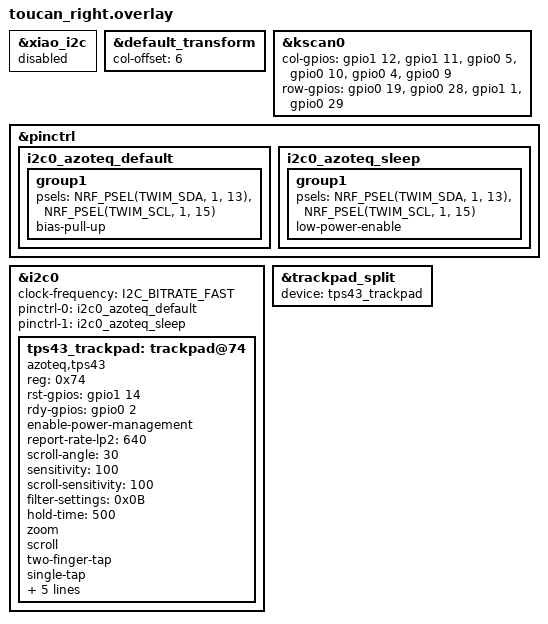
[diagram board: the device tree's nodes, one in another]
#include "toucan.dtsi"
#include <input/processors.dtsi>
#include <dt-bindings/zmk/input_transform.h>
#include <zephyr/dt-bindings/i2c/i2c.h>

&xiao_i2c {
    status = "disabled";
};

&default_transform {
    col-offset = <6>;
};

&kscan0 {
    col-gpios
    = <&gpio1 12 GPIO_ACTIVE_HIGH>
    , <&gpio1 11 GPIO_ACTIVE_HIGH>
    , <&gpio0 5 GPIO_ACTIVE_HIGH>
    , <&gpio0 10 GPIO_ACTIVE_HIGH>
    , <&gpio0 4 GPIO_ACTIVE_HIGH>
    , <&gpio0 9 GPIO_ACTIVE_HIGH>
    ;

    row-gpios
    = <&gpio0 19 (GPIO_ACTIVE_HIGH | GPIO_PULL_DOWN)>
    , <&gpio0 28 (GPIO_ACTIVE_HIGH | GPIO_PULL_DOWN)>
    , <&gpio1 1 (GPIO_ACTIVE_HIGH | GPIO_PULL_DOWN)>
    , <&gpio0 29 (GPIO_ACTIVE_HIGH | GPIO_PULL_DOWN)>
    ;
};

&pinctrl {
    i2c0_azoteq_default: i2c0_azoteq_default {
        group1 {
            psels = <NRF_PSEL(TWIM_SDA, 1, 13)>,
                    <NRF_PSEL(TWIM_SCL, 1, 15)>;
            bias-pull-up;
        };
    };

    i2c0_azoteq_sleep: i2c0_azoteq_sleep {
        group1 {
            psels = <NRF_PSEL(TWIM_SDA, 1, 13)>,
                    <NRF_PSEL(TWIM_SCL, 1, 15)>;
            low-power-enable;
        };
    };
};

&i2c0 {
    status = "okay";
    clock-frequency = <I2C_BITRATE_FAST>;
    pinctrl-0 = <&i2c0_azoteq_default>;
    pinctrl-1 = <&i2c0_azoteq_sleep>;
    pinctrl-names = "default", "sleep";

    tps43_trackpad: trackpad@74 {
        compatible = "azoteq,tps43";
        reg = <0x74>;
        status = "okay";

        rst-gpios = <&gpio1 14 GPIO_ACTIVE_HIGH>;
        rdy-gpios = <&gpio0 2 GPIO_ACTIVE_HIGH>;

        enable-power-management;
        // idle-sleep provides maximal power savings, but the pad stops responding
        // to touch until the next ZMK-active keypress while the keyboard is idle.
        // Not enabled: tps43_idle_sleeper.c already coordinates with ZMK activity state.
        report-rate-lp2 = <640>;  // 55uA in LP2 vs 174uA at the 160ms default

        // NOTE: orientation is copied from beekeeb/zmk-keyboard-toucan2 and is
        // UNVERIFIED for this retrofit — confirm on hardware and adjust
        // switch-xy / invert-x / invert-y / invert-scroll-x / invert-scroll-y.
        scroll-angle = <30>;
        sensitivity = <100>;
        scroll-sensitivity = <100>;
        filter-settings = <0x0B>;  // IIR + MAV + ALP, dynamic IIR
        hold-time = <500>;

        zoom;
        scroll;
        two-finger-tap;
        single-tap;
        press-and-hold;
        three-finger-swipe;
        three-finger-swipe-throttle-ms = <1200>;
        switch-xy;
        invert-scroll-y;
    };
};

&trackpad_split {
    device = <&tps43_trackpad>;
};
